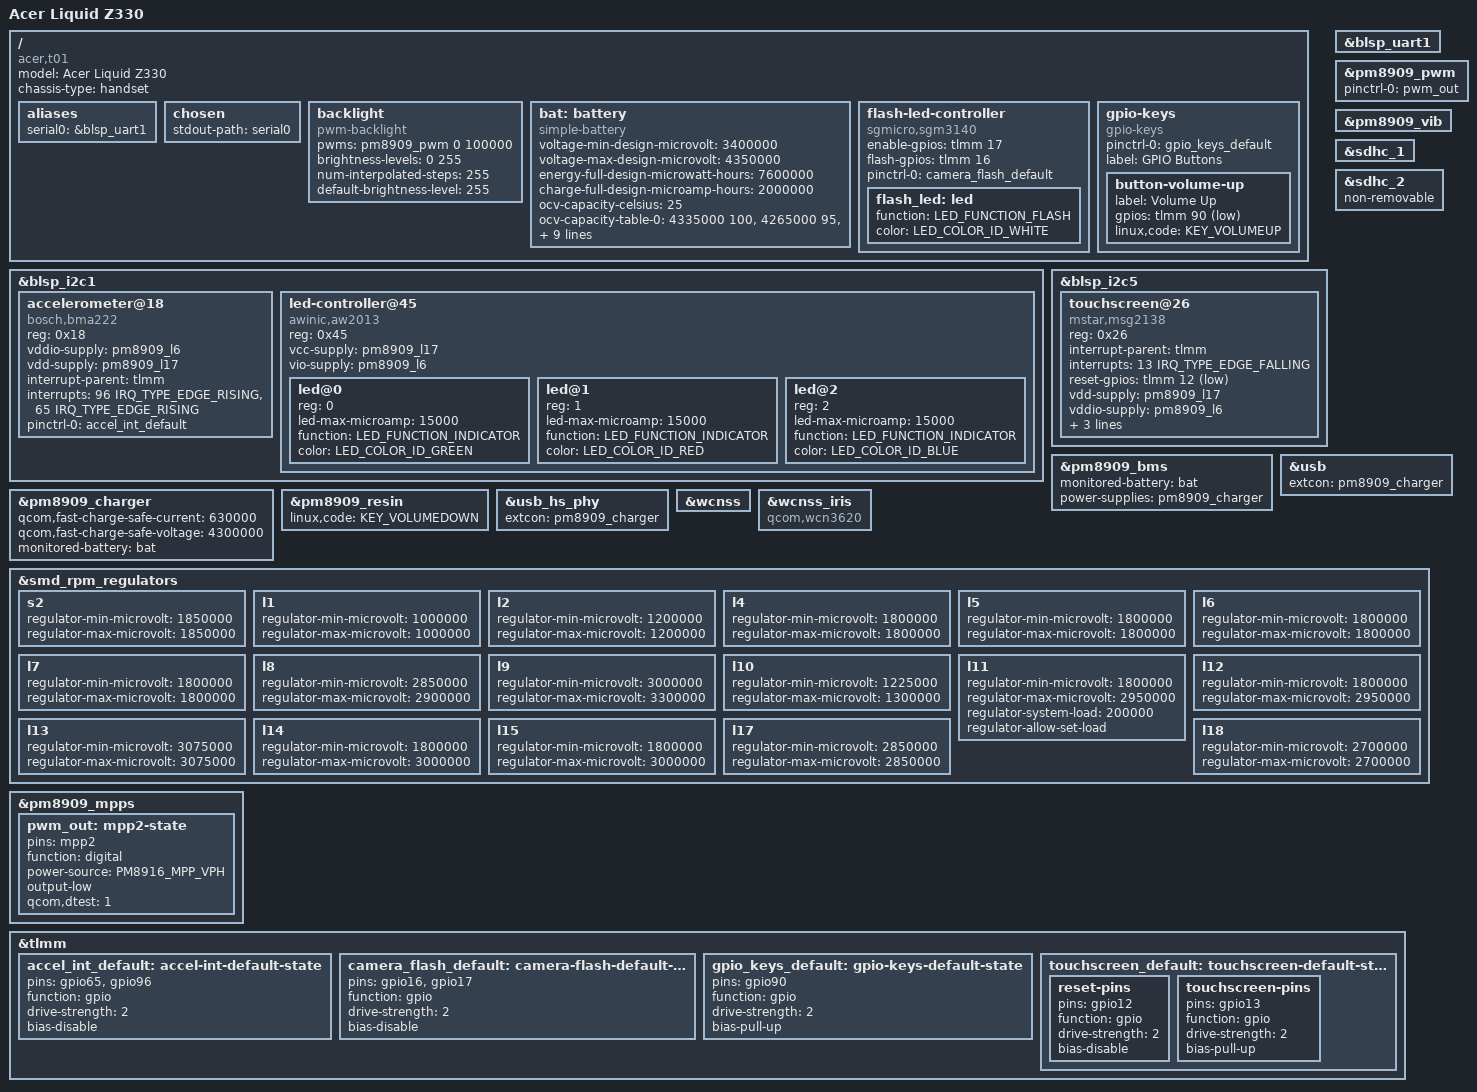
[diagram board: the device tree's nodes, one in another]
// SPDX-License-Identifier: GPL-2.0-only

/dts-v1/;

#include "qcom-msm8909-pm8909.dtsi"

#include <dt-bindings/gpio/gpio.h>
#include <dt-bindings/input/input.h>
#include <dt-bindings/interrupt-controller/irq.h>
#include <dt-bindings/leds/common.h>
#include <dt-bindings/pinctrl/qcom,pmic-mpp.h>

/ {
	model = "Acer Liquid Z330";
	compatible = "acer,t01", "qcom,msm8909";
	chassis-type = "handset";

	aliases {
		serial0 = &blsp_uart1;
	};

	chosen {
		stdout-path = "serial0";
	};

	backlight: backlight {
		compatible = "pwm-backlight";
		pwms = <&pm8909_pwm 0 100000>;

		brightness-levels = <0 255>;
		num-interpolated-steps = <255>;
		default-brightness-level = <255>;
	};

	bat: battery {
		compatible = "simple-battery";
		voltage-min-design-microvolt = <3400000>;
		voltage-max-design-microvolt = <4350000>;
		energy-full-design-microwatt-hours = <7600000>;
		charge-full-design-microamp-hours = <2000000>;

		ocv-capacity-celsius = <25>;
		ocv-capacity-table-0 = <4335000 100>, <4265000 95>,
			<4207000 90>, <4152000 85>, <4101000 80>, <4051000 75>,
			<3995000 70>, <3958000 65>, <3921000 60>, <3874000 55>,
			<3838000 50>, <3815000 45>, <3797000 40>, <3783000 35>,
			<3772000 30>, <3763000 25>, <3744000 20>, <3718000 16>,
			<3692000 13>, <3689000 11>, <3688000 10>, <3687000 9>,
			<3685000 8>, <3683000 7>, <3679000 6>, <3663000 5>,
			<3620000 4>, <3555000 3>, <3461000 2>, <3312000 1>,
			<3000000 0>;
	};

	flash-led-controller {
		compatible = "sgmicro,sgm3140";
		enable-gpios = <&tlmm 17 GPIO_ACTIVE_HIGH>;
		flash-gpios = <&tlmm 16 GPIO_ACTIVE_HIGH>;

		pinctrl-0 = <&camera_flash_default>;
		pinctrl-names = "default";

		flash_led: led {
			function = LED_FUNCTION_FLASH;
			color = <LED_COLOR_ID_WHITE>;
		};
	};

	gpio-keys {
		compatible = "gpio-keys";

		pinctrl-0 = <&gpio_keys_default>;
		pinctrl-names = "default";

		label = "GPIO Buttons";

		button-volume-up {
			label = "Volume Up";
			gpios = <&tlmm 90 GPIO_ACTIVE_LOW>;
			linux,code = <KEY_VOLUMEUP>;
		};
	};
};

&blsp_i2c1 {
	status = "okay";

	accelerometer@18 {
		compatible = "bosch,bma222";
		reg = <0x18>;

		vddio-supply = <&pm8909_l6>;
		vdd-supply = <&pm8909_l17>;

		interrupt-parent = <&tlmm>;
		interrupts = <96 IRQ_TYPE_EDGE_RISING>,
			     <65 IRQ_TYPE_EDGE_RISING>;
		interrupt-names = "INT1", "INT2";

		pinctrl-0 = <&accel_int_default>;
		pinctrl-names = "default";
	};

	led-controller@45 {
		compatible = "awinic,aw2013";
		reg = <0x45>;
		#address-cells = <1>;
		#size-cells = <0>;

		vcc-supply = <&pm8909_l17>;
		vio-supply = <&pm8909_l6>;

		led@0 {
			reg = <0>;
			led-max-microamp = <15000>;
			function = LED_FUNCTION_INDICATOR;
			color = <LED_COLOR_ID_GREEN>;
		};

		led@1 {
			reg = <1>;
			led-max-microamp = <15000>;
			function = LED_FUNCTION_INDICATOR;
			color = <LED_COLOR_ID_RED>;
		};

		led@2 {
			reg = <2>;
			led-max-microamp = <15000>;
			function = LED_FUNCTION_INDICATOR;
			color = <LED_COLOR_ID_BLUE>;
		};
	};
};

&blsp_i2c5 {
	status = "okay";

	touchscreen@26 {
		compatible = "mstar,msg2138";
		reg = <0x26>;

		interrupt-parent = <&tlmm>;
		interrupts = <13 IRQ_TYPE_EDGE_FALLING>;

		reset-gpios = <&tlmm 12 GPIO_ACTIVE_LOW>;

		vdd-supply = <&pm8909_l17>;
		vddio-supply = <&pm8909_l6>;

		touchscreen-size-x = <480>;
		touchscreen-size-y = <854>;

		pinctrl-0 = <&touchscreen_default>;
		pinctrl-names = "default";
	};
};

&blsp_uart1 {
	status = "okay";
};

&pm8909_bms {
	monitored-battery = <&bat>;
	power-supplies = <&pm8909_charger>;
	status = "okay";
};

&pm8909_charger {
	qcom,fast-charge-safe-current = <630000>;
	qcom,fast-charge-safe-voltage = <4300000>;

	monitored-battery = <&bat>;

	status = "okay";
};

&pm8909_pwm {
	pinctrl-0 = <&pwm_out>;
	pinctrl-names = "default";
	status = "okay";
};

&pm8909_resin {
	linux,code = <KEY_VOLUMEDOWN>;
	status = "okay";
};

&pm8909_vib {
	status = "okay";
};

&sdhc_1 {
	status = "okay";
};

&sdhc_2 {
	non-removable;
	status = "okay";
};

&usb {
	extcon = <&pm8909_charger>;
	status = "okay";
};

&usb_hs_phy {
	extcon = <&pm8909_charger>;
};

&wcnss {
	status = "okay";
};

&wcnss_iris {
	compatible = "qcom,wcn3620";
};

&smd_rpm_regulators {
	s2 {
		regulator-min-microvolt = <1850000>;
		regulator-max-microvolt = <1850000>;
	};

	l1 {
		regulator-min-microvolt = <1000000>;
		regulator-max-microvolt = <1000000>;
	};

	l2 {
		regulator-min-microvolt = <1200000>;
		regulator-max-microvolt = <1200000>;
	};

	l4 {
		regulator-min-microvolt = <1800000>;
		regulator-max-microvolt = <1800000>;
	};

	l5 {
		regulator-min-microvolt = <1800000>;
		regulator-max-microvolt = <1800000>;
	};

	l6 {
		regulator-min-microvolt = <1800000>;
		regulator-max-microvolt = <1800000>;
	};

	l7 {
		regulator-min-microvolt = <1800000>;
		regulator-max-microvolt = <1800000>;
	};

	l8 {
		regulator-min-microvolt = <2850000>;
		regulator-max-microvolt = <2900000>;
	};

	l9 {
		regulator-min-microvolt = <3000000>;
		regulator-max-microvolt = <3300000>;
	};

	l10 {
		regulator-min-microvolt = <1225000>;
		regulator-max-microvolt = <1300000>;
	};

	l11 {
		regulator-min-microvolt = <1800000>;
		regulator-max-microvolt = <2950000>;
		regulator-system-load = <200000>;
		regulator-allow-set-load;
	};

	l12 {
		regulator-min-microvolt = <1800000>;
		regulator-max-microvolt = <2950000>;
	};

	l13 {
		regulator-min-microvolt = <3075000>;
		regulator-max-microvolt = <3075000>;
	};

	l14 {
		regulator-min-microvolt = <1800000>;
		regulator-max-microvolt = <3000000>;
	};

	l15 {
		regulator-min-microvolt = <1800000>;
		regulator-max-microvolt = <3000000>;
	};

	l17 {
		regulator-min-microvolt = <2850000>;
		regulator-max-microvolt = <2850000>;
	};

	l18 {
		regulator-min-microvolt = <2700000>;
		regulator-max-microvolt = <2700000>;
	};
};

&pm8909_mpps {
	pwm_out: mpp2-state {
		pins = "mpp2";
		function = "digital";
		power-source = <PM8916_MPP_VPH>;
		output-low;
		qcom,dtest = <1>;
	};
};

&tlmm {
	accel_int_default: accel-int-default-state {
		pins = "gpio65", "gpio96";
		function = "gpio";
		drive-strength = <2>;
		bias-disable;
	};

	camera_flash_default: camera-flash-default-state {
		pins = "gpio16", "gpio17";
		function = "gpio";
		drive-strength = <2>;
		bias-disable;
	};

	gpio_keys_default: gpio-keys-default-state {
		pins = "gpio90";
		function = "gpio";
		drive-strength = <2>;
		bias-pull-up;
	};

	touchscreen_default: touchscreen-default-state {
		reset-pins {
			pins = "gpio12";
			function = "gpio";
			drive-strength = <2>;
			bias-disable;
		};

		touchscreen-pins {
			pins = "gpio13";
			function = "gpio";
			drive-strength = <2>;
			bias-pull-up;
		};
	};
};
